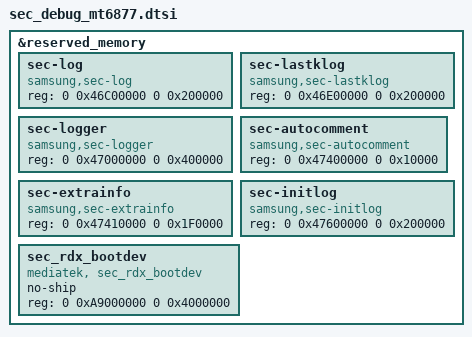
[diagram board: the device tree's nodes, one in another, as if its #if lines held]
/* SAMSUNG DEBUG device tree source
 *
 * Copyright (c) 2022 Samsung Electronics Co., Ltd.
 *		http://www.samsung.com
 *
 * This program is free software; you can redistribute it and/or modify
 * it under the terms of the GNU General Public License version 2 as
 * published by the Free Software Foundation.
 */


&reserved_memory {
		sec-log {
			compatible = "samsung,sec-log";
			reg = <0 0x46C00000 0 0x200000>;
		};

		sec-lastklog {
			compatible = "samsung,sec-lastklog";
			reg = <0 0x46E00000 0 0x200000>;
		};

		sec-logger {
			compatible = "samsung,sec-logger";
			reg = <0 0x47000000 0 0x400000>;
		};

		sec-autocomment {
			compatible = "samsung,sec-autocomment";
			reg = <0 0x47400000 0 0x10000>;
		};
		
		sec-extrainfo {
			compatible = "samsung,sec-extrainfo";
			reg = <0 0x47410000 0 0x1F0000>;
		};
#ifdef CONFIG_SEC_DEBUG_INIT_LOG
		sec-initlog {
			compatible = "samsung,sec-initlog";		
			reg = <0 0x47600000 0 0x200000>;
		};
#endif
#ifdef CONFIG_SEC_DUMP_SINK
		sec_rdx_bootdev {
			compatible = "mediatek, sec_rdx_bootdev";
			no-ship;
			reg = <0 0xA9000000 0 0x4000000>;
		};
#endif
};

